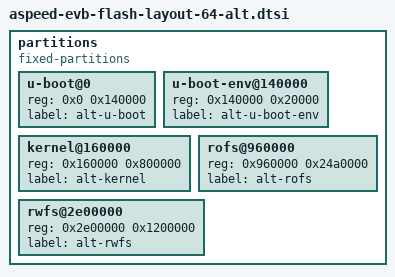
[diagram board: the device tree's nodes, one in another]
// SPDX-License-Identifier: GPL-2.0+
/*
 * Copyright (C) 2022 ASPEED.
 */

partitions {
	compatible = "fixed-partitions";
	#address-cells = <1>;
	#size-cells = <1>;

	u-boot@0 {
		reg = <0x0 0x140000>; // 1280KB
		label = "alt-u-boot";
	};

	u-boot-env@140000 {
		reg = <0x140000 0x20000>; // 128KB
		label = "alt-u-boot-env";
	};

	kernel@160000 {
		reg = <0x160000 0x800000>; // 8MB
		label = "alt-kernel";
	};

	rofs@960000 {
		reg = <0x960000 0x24a0000>; // 36.625MB
		label = "alt-rofs";
	};

	rwfs@2e00000 {
		reg = <0x2e00000 0x1200000>; // 18MB
		label = "alt-rwfs";
	};
};
